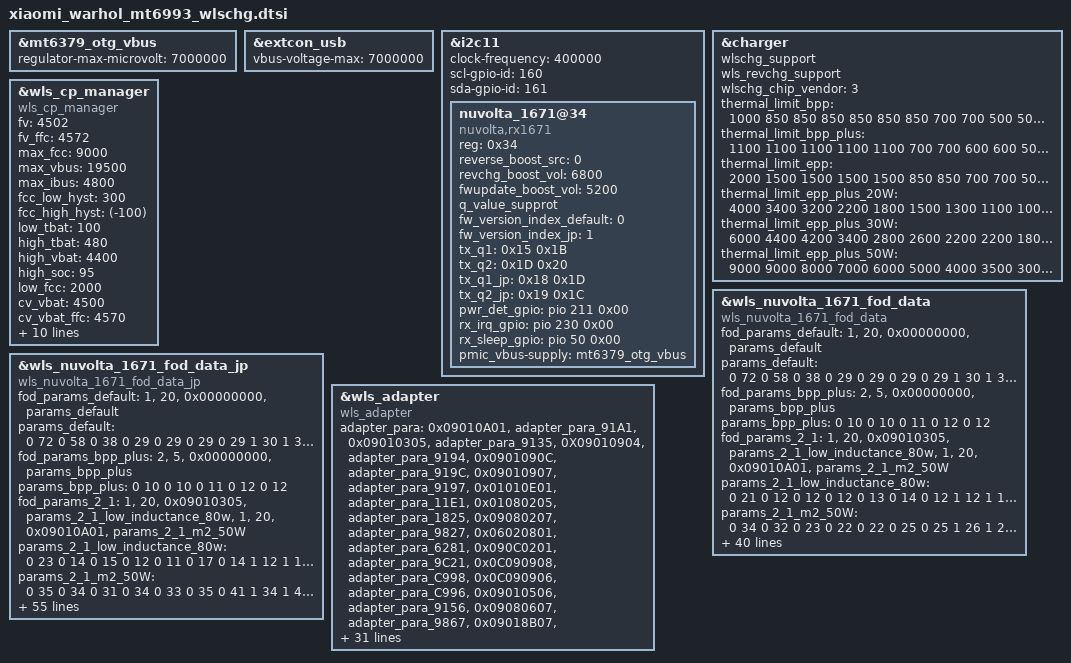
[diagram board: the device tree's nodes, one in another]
&mt6379_otg_vbus {
	regulator-max-microvolt = <7000000>;
};

&extcon_usb {
	vbus-voltage-max = <7000000>;
};

&i2c11 {
	clock-frequency = <400000>;
	scl-gpio-id = <160>;
	sda-gpio-id = <161>;
	nuvolta_1671@34{
		compatible = "nuvolta,rx1671";
		reg = <0x34>;
		reverse_boost_src = <0>;
		revchg_boost_vol = <6800>;
		fwupdate_boost_vol = <5200>;
		//support-hall = <1>;
		q_value_supprot;
		fw_version_index_default = <0>;
		fw_version_index_jp = <1>;
		tx_q1 = /bits/ 8 <0x15 0x1B>;
		tx_q2 = /bits/ 8 <0x1D 0x20>;
		tx_q1_jp = /bits/ 8 <0x18 0x1D>;
		tx_q2_jp = /bits/ 8 <0x19 0x1C>;
		pwr_det_gpio = <&pio 211 0x00>;
		rx_irq_gpio = <&pio 230 0x00>;
		rx_sleep_gpio = <&pio 50 0x00>;
		//hall-n-int = <&pio 155 IRQ_TYPE_EDGE_FALLING>;
		//hall-s-int = <&pio 154 IRQ_TYPE_EDGE_FALLING>;
		pmic_vbus-supply = <&mt6379_otg_vbus>;
	};
};

&charger {
	wlschg_support;
	wls_revchg_support;
	wlschg_chip_vendor = <3>;
	/* wls thermal config */
	thermal_limit_bpp = <1000 850 850 850 850 850 850 700 700 500 500 500 500 500 400 300>;
	thermal_limit_bpp_plus = <1100 1100 1100 1100 1100 700 700 600 600 500 500 500 500 500 400 300>;
	thermal_limit_epp = <2000 1500 1500 1500 1500 850 850 700 700 500 500 500 500 500 400 300>;
	thermal_limit_epp_plus_20W = <4000 3400 3200 2200 1800 1500 1300 1100 1000 800 700 600 500 500 400 300>;
	thermal_limit_epp_plus_30W = <6000 4400 4200 3400 2800 2600 2200 2200 1800 1100 1000 800 700 600 500 400>;
	thermal_limit_epp_plus_50W = <9000 9000 8000 7000 6000 5000 4000 3500 3000 2500 2000 1500 1000 800 500 400>;
};

&wls_cp_manager {
	compatible = "wls_cp_manager";
	fv = <4502>;
	fv_ffc = <4572>;
	max_fcc = <9000>;
	max_vbus = <19500>;
	max_ibus = <4800>;
	fcc_low_hyst = <300>;
	fcc_high_hyst = <(-100)>;
	low_tbat = <100>;
	high_tbat = <480>;
	high_vbat = <4400>;
	high_soc = <95>;
	low_fcc = <2000>;
	cv_vbat = <4500>;
	cv_vbat_ffc = <4570>;
	cv_ibat = <1500>;
	vbus_low_gap_div = <500>;
	vbus_high_gap_div = <600>;
	wls_cm_ibus_gap = <600>;
	switch2_1_enter = <6000>;
	switch2_1_exit = <8000>;
	support_pmic_parachg;
	pmic_parachg_icl = <100>;
	max_curr_duration_4_1 = <240>;
	max_curr_duration_2_1 = <90>;
};

&wls_nuvolta_1671_fod_data {
	compatible = "wls_nuvolta_1671_fod_data";
	fod_params_default =
		"1", "20", "0x00000000", "params_default";
	params_default = /bits/ 8 <
		0	72
		0	58
		0	38
		0	29
		0	29
		0	29
		0	29
		1	30
		1	39
		1	40
		1	40
		1	62
		2	59
		2	64
		2	72
		2	75
		2	85
		2	95
		2	99
		2	101
	>;

	fod_params_bpp_plus =
		"2", "5", "0x00000000", "params_bpp_plus";
	params_bpp_plus = /bits/ 8 <
		0  10
		0  10
		0  11
		0  12
		0  12
	>;

/* type, length, uuid, params */
	fod_params_2_1 =
		"1", "20", "0x09010305", "params_2_1_low_inductance_80w",
		"1", "20", "0x09010A01", "params_2_1_m2_50W";

	params_2_1_low_inductance_80w = /bits/ 8 <
		0	21
		0	12
		0	12
		0	12
		0	13
		0	14
		0	12
		1	12
		1	13
		1	17
		1	17
		1	20
		2	12
		2	14
		2	14
		2	19
		2	25
		2	31
		2	31
		2	33
	>;

	params_2_1_m2_50W = /bits/ 8 <
		0	34
		0	32
		0	23
		0	22
		0	22
		0	25
		0	25
		1	26
		1	29
		1	32
		1	30
		1	25
		2	19
		2	17
		2	18
		2	22
		2	33
		2	36
		2	36
		2	38
	>;

	/* type, length, uuid, params */
	fod_params =
		"1", "20", "0x0901090C", "params_k8_100W",
		"0", "12", "0x09010305", "params_low_inductance_80w",
		"1", "20", "0x09010901", "params_l2_50W",
		"1", "20", "0x09010407", "params_white_stand_30W",
		"1", "20", "0x09010904", "params_k1_80W",
		"0", "12", "0x09010A01", "params_m2_50W",
		"1", "20", "0x0901010B", "params_j1s_55W",
		"1", "20", "0x09080108", "params_zimi_20W",
		"1", "20", "0x09010A07", "params_double_coil_30W",
		"1", "20", "0x0C090908", "params_multcoil_20W",
		"1", "20", "0x06020801", "params_zimi_car_20W",
		"1", "20", "0x09080607", "params_bluetooth_30W",
		"1", "20", "0x07030801", "params_power_bank_30W";

	/* gain, offset */
	params_k8_100W = /bits/ 8 <
		0	35
		0	28
		0	25
		0	25
		0	24
		0	28
		0	27
		1	28
		1	31
		1	37
		1	40
		1	44
		2	39
		2	39
		2	44
		2	44
		2	50
		2	56
		2	60
		2	83
	>;

	params_low_inductance_80w = /bits/ 8 <
		10	10
		10	0
		8	0
		0	(-3)
		0	(-2)
		0	0
		0	7
		0	10
		0	15
		0	13
		0	5
		0	5
	>;

	params_l2_50W = /bits/ 8 <
		0	32
		0	29
		0	27
		0	27
		0	27
		0	28
		0	27
		1	27
		1	28
		1	26
		1	34
		1	32
		2	26
		2	31
		2	30
		2	33
		2	29
		2	33
		2	26
		2	38
	>;

	params_white_stand_30W = /bits/ 8 <
		0	37
		0	38
		0	28
		0	29
		0	27
		0	30
		0	31
		1	31
		1	31
		1	36
		1	40
		1	44
		2	38
		2	38
		2	38
		2	38
		2	38
		2	38
		2	38
		2	38
	>;

	params_k1_80W = /bits/ 8 <
		0	35
		0	30
		0	24
		0	24
		0	24
		0	29
		0	33
		1	31
		1	35
		1	40
		1	42
		1	48
		2	41
		2	47
		2	46
		2	52
		2	59
		2	62
		2	66
		2	91
	>;

	params_m2_50W = /bits/ 8 <
		10	40
		10	30
		10	30
		8	37
		7	36
		7	43
		7	40
		7	37
		7	34
		7	34
		7	37
		7	37
	>;

	params_j1s_55W = /bits/ 8 <
		0	32
		0	29
		0	27
		0	27
		0	27
		0	28
		0	27
		1	27
		1	28
		1	26
		1	34
		1	32
		2	26
		2	31
		2	30
		2	33
		2	29
		2	33
		2	26
		2	38
	>;

	params_zimi_20W = /bits/ 8 <
		0	32
		0	29
		0	27
		0	27
		0	27
		0	28
		0	27
		1	27
		1	28
		1	26
		1	34
		1	32
		2	26
		2	31
		2	30
		2	33
		2	29
		2	33
		2	26
		2	38
	>;

	params_double_coil_30W = /bits/ 8 <
		0	40
		0	31
		0	38
		0	25
		0	26
		0	30
		0	34
		1	40
		1	44
		1	49
		1	55
		1	60
		2	62
		2	62
		2	64
		2	64
		2	64
		2	67
		2	67
		2	69
	>;

	params_power_bank_30W = /bits/ 8 <
		0	32
		0	29
		0	27
		0	27
		0	27
		0	28
		0	27
		1	27
		1	28
		1	26
		1	34
		1	32
		2	26
		2	31
		2	30
		2	33
		2	29
		2	33
		2	26
		2	38
	>;

	params_multcoil_20W = /bits/ 8 <
		0	32
		0	29
		0	27
		0	27
		0	27
		0	28
		0	27
		1	27
		1	28
		1	30
		1	31
		1	34
		2	30
		2	31
		2	30
		2	31
		2	28
		2	33
		2	26
		2	38
	>;

	params_zimi_car_20W = /bits/ 8 <
		0	72
		0	58
		0	23
		0	23
		0	23
		0	29
		0	29
		1	30
		1	39
		1	39
		1	40
		1	62
		2	59
		2	64
		2	72
		2	75
		2	85
		2	95
		2	99
		2	101
	>;

	params_bluetooth_30W = /bits/ 8 <
		0	32
		0	29
		0	27
		0	27
		0	27
		0	28
		0	27
		1	27
		1	28
		1	26
		1	34
		1	32
		2	26
		2	31
		2	30
		2	33
		2	29
		2	33
		2	26
		2	38
	>;
};

&wls_nuvolta_1671_fod_data_jp {
	compatible = "wls_nuvolta_1671_fod_data_jp";
	fod_params_default =
		"1", "20", "0x00000000", "params_default";
	params_default = /bits/ 8 <
		0	72
		0	58
		0	38
		0	29
		0	29
		0	29
		0	29
		1	30
		1	39
		1	40
		1	40
		1	62
		2	59
		2	64
		2	72
		2	75
		2	85
		2	95
		2	99
		2	101
	>;

	fod_params_bpp_plus =
		"2", "5", "0x00000000", "params_bpp_plus";
	params_bpp_plus = /bits/ 8 <
		0  10
		0  10
		0  11
		0  12
		0  12
	>;

/* type, length, uuid, params */
	fod_params_2_1 =
		"1", "20", "0x09010305", "params_2_1_low_inductance_80w",
		"1", "20", "0x09010A01", "params_2_1_m2_50W";

	params_2_1_low_inductance_80w = /bits/ 8 <
		0	23
		0	14
		0	15
		0	12
		0	11
		0	17
		0	14
		1	12
		1	16
		1	18
		1	20
		1	20
		2	16
		2	16
		2	20
		2	22
		2	25
		2	31
		2	31
		2	33
	>;

	params_2_1_m2_50W = /bits/ 8 <
		0	35
		0	34
		0	31
		0	34
		0	33
		0	35
		0	41
		1	34
		1	40
		1	37
		1	43
		1	34
		2	18
		2	23
		2	21
		2	24
		2	33
		2	36
		2	36
		2	38
	>;

	/* type, length, uuid, params */
	fod_params =
		"1", "20", "0x0901090C", "params_k8_100W",
		"0", "12", "0x09010305", "params_low_inductance_80w",
		"1", "20", "0x09010901", "params_l2_50W",
		"1", "20", "0x09010407", "params_white_stand_30W",
		"1", "20", "0x09010904", "params_k1_80W",
		"0", "12", "0x09010A01", "params_m2_50W",
		"1", "20", "0x0901010B", "params_j1s_55W",
		"0", "16", "0x01080205", "params_zimi_car_50W",
		"0", "16", "0x09080207", "params_zimi_car_30W",
		"0", "16", "0x09010907", "params_redmi_disc_30W",
		"1", "20", "0x09080108", "params_zimi_20W",
		"0", "16", "0x09010506", "params_moving_20W",
		"1", "20", "0x09010A07", "params_double_coil_30W",
		"0", "16", "0x06010101", "params_white_20W",
		"1", "20", "0x0C090908", "params_multcoil_20W",
		"1", "20", "0x06020801", "params_zimi_car_20W",
		"1", "20", "0x09080607", "params_bluetooth_30W",
		"1", "20", "0x07030801", "params_power_bank_30W";

	/* gain, offset */
	params_k8_100W = /bits/ 8 <
		0	35
		0	28
		0	25
		0	27
		0	24
		0	31
		0	32
		1	31
		1	30
		1	40
		1	41
		1	44
		2	41
		2	45
		2	50
		2	51
		2	50
		2	61
		2	65
		2	83
	>;

	params_low_inductance_80w = /bits/ 8 <
		10	10
		10	0
		8	0
		0	(-3)
		0	(-2)
		0	0
		0	7
		0	7
		0	10
		0	13
		0	5
		0	5
	>;

	params_l2_50W = /bits/ 8 <
		0	32
		0	29
		0	27
		0	27
		0	27
		0	28
		0	27
		1	27
		1	28
		1	30
		1	31
		1	34
		2	30
		2	31
		2	30
		2	31
		2	28
		2	33
		2	26
		2	38
	>;

	params_white_stand_30W = /bits/ 8 <
		0	37
		0	35
		0	28
		0	27
		0	27
		0	30
		0	30
		1	31
		1	31
		1	40
		1	40
		1	44
		2	38
		2	38
		2	38
		2	38
		2	38
		2	38
		2	38
		2	38
	>;

	params_k1_80W = /bits/ 8 <
		0	35
		0	33
		0	26
		0	26
		0	24
		0	29
		0	33
		1	31
		1	35
		1	38
		1	42
		1	50
		2	43
		2	47
		2	49
		2	52
		2	59
		2	62
		2	66
		2	91
	>;

	params_m2_50W = /bits/ 8 <
		10	40
		10	30
		10	30
		8	68
		7	68
		7	68
		7	71
		7	67
		7	62
		7	60
		7	62
		7	62
	>;

	params_j1s_55W = /bits/ 8 <
		0	32
		0	29
		0	27
		0	27
		0	27
		0	28
		0	27
		1	27
		1	28
		1	26
		1	34
		1	32
		2	26
		2	31
		2	30
		2	33
		2	29
		2	33
		2	26
		2	38
	>;

	params_zimi_car_50W = /bits/ 8 <
		120  25
		120  10
		120  15
		120  20
		102  19
		111  25
		123  25
		123  30
		129  15
		124  20
		126  20
		126  20
		112  40
		112  40
		112  40
		112  40
	>;

	params_zimi_car_30W = /bits/ 8 <
		128  40
		127  34
		127  34
		127  34
		126  34
		125  38
		125  38
		124  41
		124  43
		123  40
		126  36
		126  36
		128  40
		128  40
		128  40
		128  40
	>;

	params_redmi_disc_30W = /bits/ 8 <
		125	55
		125	55
		125	55
		125	55
		125	50
		125	50
		126	60
		127	55
		128	70
		129	70
		255	127
		154	100
		144	80
		134	60
		134	60
		134	60
	>;

	params_zimi_20W = /bits/ 8 <
		0	32
		0	29
		0	27
		0	27
		0	27
		0	28
		0	27
		1	27
		1	28
		1	26
		1	34
		1	32
		2	26
		2	31
		2	30
		2	33
		2	29
		2	33
		2	26
		2	38
	>;

	params_moving_20W = /bits/ 8 <
		118	50
		116	50
		115	50
		114	50
		114	50
		114	44
		114	36
		114	36
		114	36
		114	36
		255	127
		154	100
		144	80
		134	60
		134	60
		134	60
	>;

	params_double_coil_30W = /bits/ 8 <
		0	40
		0	31
		0	38
		0	25
		0	26
		0	30
		0	34
		1	40
		1	44
		1	49
		1	55
		1	60
		2	62
		2	62
		2	64
		2	64
		2	64
		2	67
		2	67
		2	69
	>;

	params_power_bank_30W = /bits/ 8 <
		0	32
		0	29
		0	27
		0	27
		0	27
		0	28
		0	27
		1	27
		1	28
		1	26
		1	34
		1	32
		2	26
		2	31
		2	30
		2	33
		2	29
		2	33
		2	26
		2	38
	>;

	params_white_20W = /bits/ 8 <
		120	50
		120	55
		121	55
		121	55
		121	65
		122	70
		122	80
		123	80
		125	85
		127	85
		255	127
		154	100
		144	80
		134	60
		134	60
		134	60
	>;

	params_multcoil_20W = /bits/ 8 <
		0	32
		0	29
		0	27
		0	27
		0	27
		0	28
		0	27
		1	27
		1	28
		1	30
		1	31
		1	34
		2	30
		2	31
		2	30
		2	31
		2	28
		2	33
		2	26
		2	38
	>;

	params_zimi_car_20W = /bits/ 8 <
		0	72
		0	58
		0	23
		0	23
		0	23
		0	29
		0	29
		1	30
		1	39
		1	39
		1	40
		1	62
		2	59
		2	64
		2	72
		2	75
		2	85
		2	95
		2	99
		2	101
	>;

	params_bluetooth_30W = /bits/ 8 <
		0	32
		0	29
		0	27
		0	27
		0	27
		0	28
		0	27
		1	27
		1	28
		1	26
		1	34
		1	32
		2	26
		2	31
		2	30
		2	33
		2	29
		2	33
		2	26
		2	38
	>;
};

&wls_adapter {
	compatible = "wls_adapter";

	adapter_para =
		"0x09010A01", "adapter_para_91A1",	/* XIAOMI_TX_UUID_LOW_INDUCTANCE_50W */
		"0x09010305", "adapter_para_9135",	/* XIAOMI_TX_UUID_LOW_INDUCTANCE_80W */
		"0X09010904", "adapter_para_9194",	/* XIAOMI_TX_UUID_SAILBOAT_80W */
		"0x0901090C", "adapter_para_919C",	/* XIAOMI_TX_UUID_SAILBOAT_100W */
		"0x09010907", "adapter_para_9197",	/* XIAOMI_TX_UUID_REDMI_30W */
		"0x01010E01", "adapter_para_11E1",	/* XIAOMI_TX_UUID_TRAIN_20W */
		"0x01080205", "adapter_para_1825",	/* XIAOMI_TX_UUID_ZIMI_CAR_50W */
		"0x09080207", "adapter_para_9827",	/* XIAOMI_TX_UUID_ZIMI_CAR_30W */
		"0x06020801", "adapter_para_6281",	/* XIAOMI_TX_UUID_ZIMI_CAR_20W */
		"0x090C0201", "adapter_para_9C21",	/* XIAOMI_TX_UUID_KUKE_CAR_50W */
		"0x0C090908", "adapter_para_C998",	/* XIAOMI_TX_UUID_MULTI_COIL2_20W */
		"0x0C090906", "adapter_para_C996",	/* XIAOMI_TX_UUID_MULTI_COIL_20W */
		"0x09010506", "adapter_para_9156",	/* XIAOMI_TX_UUID_MOVING_PLATE_20W */
		"0x09080607", "adapter_para_9867",	/* XIAOMI_TX_UUID_MUSICAL_BOX_30W */
		"0x09018B07", "adapter_para_918B7";	/* XIAOMI_TX_UUID_MAGNET_30W */

	/* standard_tx, musical_box, plate_tx, car_mounted, train_tx, redmi_30w_tx, sailboat_tx, low_inductance_50w_tx, low_inductance_80w_tx, support_fan, magnet_tx*/
	adapter_para_91A1 = "1", "0", "0", "0", "0", "0", "0", "1", "0", "1", "0";
	adapter_para_9135 = "0", "0", "0", "0", "0", "0", "0", "0", "1", "1", "0";
	adapter_para_9194 = "0", "0", "0", "0", "0", "0", "1", "0", "0", "1", "0";
	adapter_para_919C = "0", "0", "0", "0", "0", "0", "1", "0", "0", "1", "0";
	adapter_para_9197 = "0", "0", "0", "0", "0", "1", "0", "0", "0", "1", "0";
	adapter_para_11E1 = "0", "0", "0", "0", "1", "0", "0", "0", "0", "0", "0";
	adapter_para_1825 = "0", "0", "0", "1", "0", "0", "0", "0", "0", "0", "0";
	adapter_para_9827 = "0", "0", "0", "1", "0", "0", "0", "0", "0", "0", "0";
	adapter_para_6281 = "0", "0", "0", "1", "0", "0", "0", "0", "0", "0", "0";
	adapter_para_9C21 = "0", "0", "0", "1", "0", "0", "0", "0", "0", "0", "0";
	adapter_para_C998 = "0", "0", "1", "0", "0", "0", "0", "0", "0", "0", "0";
	adapter_para_C996 = "0", "0", "1", "0", "0", "0", "0", "0", "0", "0", "0";
	adapter_para_9156 = "0", "0", "1", "0", "0", "0", "0", "0", "0", "0", "0";
	adapter_para_9867 = "0", "1", "0", "0", "0", "0", "0", "0", "0", "0", "0";
	adapter_para_918B7 = "0", "0", "0", "0", "0", "0", "0", "0", "0", "0", "1";
};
